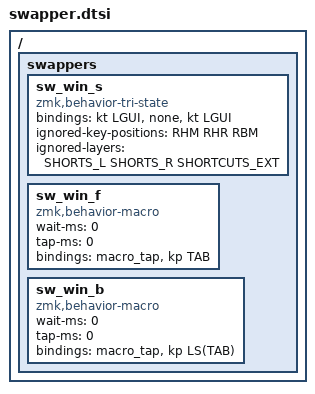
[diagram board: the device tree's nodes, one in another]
/*
*
* Copyright (c) 2022 Rafael Romão
* SPDX-License-Identifier: MIT
*
*/
/*                KEY POSITIONS

  ╭─────────────────────╮ ╭─────────────────────╮
  │ LTP LTR LTM LTI LTC │ │ RTC RTI RTM RTR RTP │
  │ LHP LHR LHM LHI LHC │ │ RHC RHI RHM RHR RHP │
  │ LBP LBR LBM LBI LBC │ │ RBC RBI RBM RBR RBP │
  ╰───────╮ L2  L1  L0  │ │ R0  R1  R2  ╭───────╯
          ╰─────────────╯ ╰─────────────╯ */


/ {
    swappers {
        sw_win_s: sw_win_s {
            compatible = "zmk,behavior-tri-state";
            #binding-cells = <0>;
            bindings = <&kt LGUI>, <&none>, <&kt LGUI>;
            ignored-key-positions = <RHM RHR RBM>;
            ignored-layers = <SHORTS_L SHORTS_R SHORTCUTS_EXT>;
        };
        sw_win_f: sw_win_f {
            wait-ms = <0>;
            tap-ms = <0>;
            compatible = "zmk,behavior-macro";
            #binding-cells = <0>;
            bindings = <&macro_tap &kp TAB>;
        };
        sw_win_b: sw_win_b {
            wait-ms = <0>;
            tap-ms = <0>;
            compatible = "zmk,behavior-macro";
            #binding-cells = <0>;
            bindings = <&macro_tap &kp LS(TAB)>;
        };
    };
};
